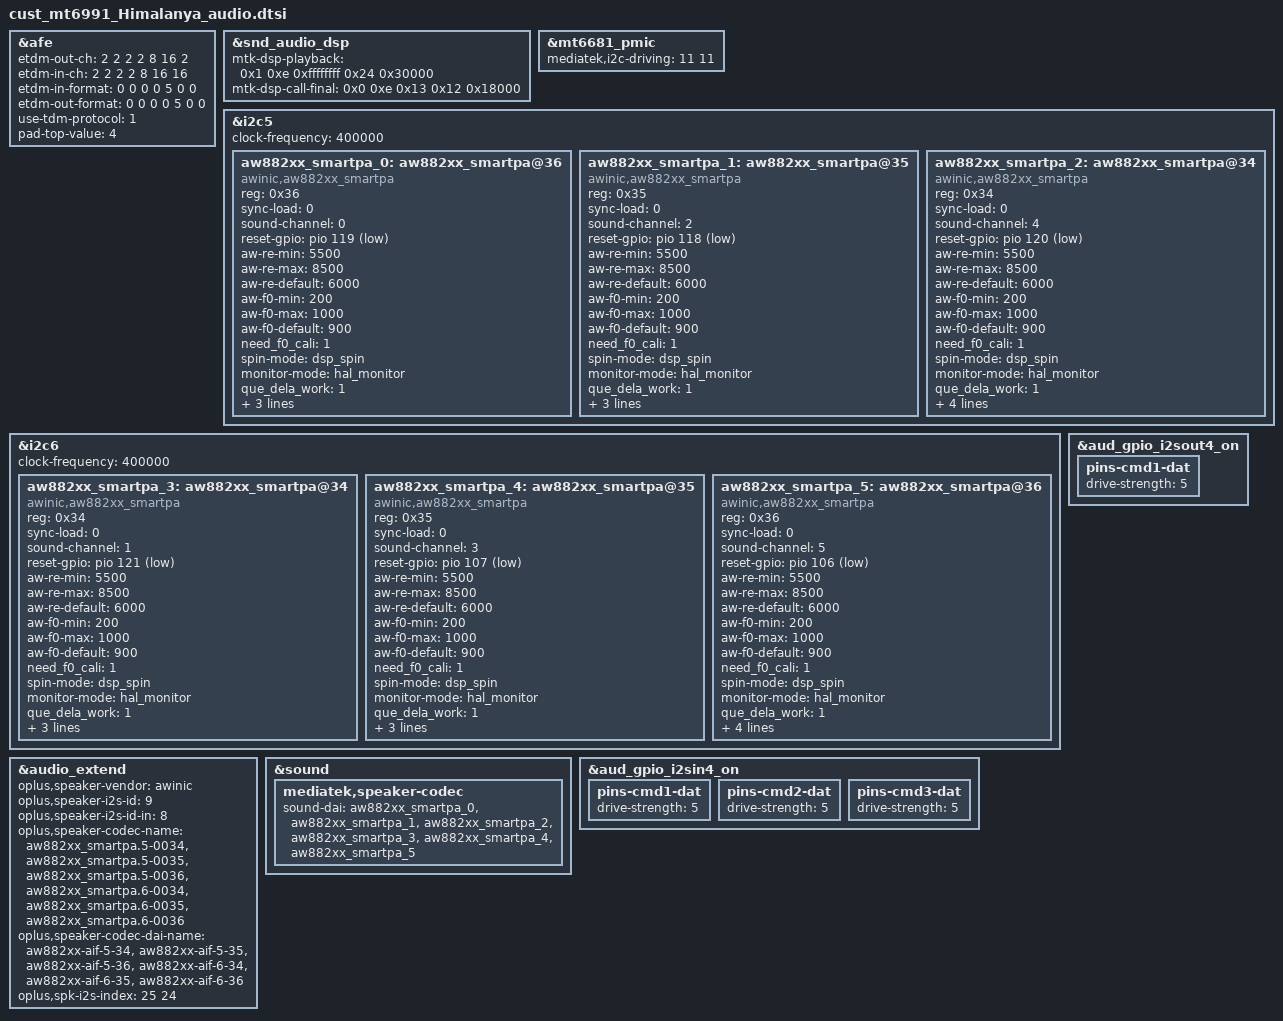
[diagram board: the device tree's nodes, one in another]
// SPDX-License-Identifier: GPL-2.0
/* Copyright (c) 2020 MediaTek Inc. */
#include <dt-bindings/pinctrl/mt6373-pinfunc.h>

&afe {
    etdm-out-ch = <2 2 2 2 8 16 2>;
    etdm-in-ch = <2 2 2 2 8 16 16>;
    etdm-in-format = <0 0 0 0 5 0 0>;
    etdm-out-format = <0 0 0 0 5 0 0>;
    use-tdm-protocol = <1>;
    pad-top-value = <4>;
};


&snd_audio_dsp {
    mtk-dsp-playback = <0x1 0xe 0xffffffff 0x24 0x30000>;
    mtk-dsp-call-final = <0x0 0xe 0x13 0x12 0x18000>;
};

&mt6681_pmic {
	mediatek,i2c-driving = <11 11>;
};

&i2c5 {
	clock-frequency = <400000>;

/* AWINIC AW882XX mono Smart PA */

aw882xx_smartpa_0: aw882xx_smartpa@36 {
	 compatible = "awinic,aw882xx_smartpa";
	 reg = <0x36>;
	 #address-cells = <1>;
	 #size-cells = <0>;
	 #sound-dai-cells = <0>;
	 sync-load = <0>;
	 sound-channel = <0>;
	 reset-gpio = <&pio 119 0x1>;
	 aw-re-min = <5500>;
	 aw-re-max= <8500>;
	 aw-re-default = <6000>;
	 aw-f0-min = <200>;
	 aw-f0-max = <1000>;
	 aw-f0-default = <900>;
	 //aw-cali-mode = "none";
	 need_f0_cali = <1>;
	 spin-mode = "dsp_spin";
	 monitor-mode = "hal_monitor";
	 que_dela_work = <1>;
	 fade-flag = <0>;
	 need-add-bus-id = <1>;
	 default-chip-id = <0x2113>;
	 status = "okay";
};

aw882xx_smartpa_1: aw882xx_smartpa@35 {
	 compatible = "awinic,aw882xx_smartpa";
	 reg = <0x35>;
	 #address-cells = <1>;
	 #size-cells = <0>;
	 #sound-dai-cells = <0>;
	 sync-load = <0>;
	 sound-channel = <2>;
	 reset-gpio = <&pio 118 0x1>;
	 aw-re-min = <5500>;
	 aw-re-max= <8500>;
	 aw-re-default = <6000>;
	 aw-f0-min = <200>;
	 aw-f0-max = <1000>;
	 aw-f0-default = <900>;
	 //aw-cali-mode = "none";
	 need_f0_cali = <1>;
	 spin-mode = "dsp_spin";
	 monitor-mode = "hal_monitor";
	 que_dela_work = <1>;
	 fade-flag = <0>;
	 need-add-bus-id = <1>;
	 default-chip-id = <0x2113>;
	 status = "okay";
};

aw882xx_smartpa_2: aw882xx_smartpa@34 {
	 compatible = "awinic,aw882xx_smartpa";
	 reg = <0x34>;
	 #address-cells = <1>;
	 #size-cells = <0>;
	 #sound-dai-cells = <0>;
	 sync-load = <0>;
	 sound-channel = <4>;
	 reset-gpio = <&pio 120 0x1>;
	 aw-re-min = <5500>;
	 aw-re-max= <8500>;
	 aw-re-default = <6000>;
	 aw-f0-min = <200>;
	 aw-f0-max = <1000>;
	 aw-f0-default = <900>;
	 //aw-cali-mode = "none";
	 need_f0_cali = <1>;
	 spin-mode = "dsp_spin";
	 monitor-mode = "hal_monitor";
	 que_dela_work = <1>;
	 fade-flag = <0>;
	 need-add-bus-id = <1>;
	 default-chip-id = <0x2113>;
	 cali-disable = <1>;
	 status = "okay";
};

};

&i2c6 {
	clock-frequency = <400000>;

/* AWINIC AW882XX mono Smart PA */

aw882xx_smartpa_3: aw882xx_smartpa@34 {
	 compatible = "awinic,aw882xx_smartpa";
	 reg = <0x34>;
	 #address-cells = <1>;
	 #size-cells = <0>;
	 #sound-dai-cells = <0>;
	 sync-load = <0>;
	 sound-channel = <1>;
	 reset-gpio = <&pio 121 0x1>;
	 aw-re-min = <5500>;
	 aw-re-max= <8500>;
	 aw-re-default = <6000>;
	 aw-f0-min = <200>;
	 aw-f0-max = <1000>;
	 aw-f0-default = <900>;
	 //aw-cali-mode = "none";
	 need_f0_cali = <1>;
	 spin-mode = "dsp_spin";
	 monitor-mode = "hal_monitor";
	 que_dela_work = <1>;
	 fade-flag = <0>;
	 need-add-bus-id = <1>;
	 default-chip-id = <0x2113>;
	 status = "okay";
};

aw882xx_smartpa_4: aw882xx_smartpa@35 {
	 compatible = "awinic,aw882xx_smartpa";
	 reg = <0x35>;
	 #address-cells = <1>;
	 #size-cells = <0>;
	 #sound-dai-cells = <0>;
	 sync-load = <0>;
	 sound-channel = <3>;
	 reset-gpio = <&pio 107 0x1>;
	 aw-re-min = <5500>;
	 aw-re-max= <8500>;
	 aw-re-default = <6000>;
	 aw-f0-min = <200>;
	 aw-f0-max = <1000>;
	 aw-f0-default = <900>;
	 //aw-cali-mode = "none";
	 need_f0_cali = <1>;
	 spin-mode = "dsp_spin";
	 monitor-mode = "hal_monitor";
	 que_dela_work = <1>;
	 fade-flag = <0>;
	 need-add-bus-id = <1>;
	 default-chip-id = <0x2113>;
	 status = "okay";
};

aw882xx_smartpa_5: aw882xx_smartpa@36 {
	 compatible = "awinic,aw882xx_smartpa";
	 reg = <0x36>;
	 #address-cells = <1>;
	 #size-cells = <0>;
	 #sound-dai-cells = <0>;
	 sync-load = <0>;
	 sound-channel = <5>;
	 reset-gpio = <&pio 106 0x1>;
	 aw-re-min = <5500>;
	 aw-re-max= <8500>;
	 aw-re-default = <6000>;
	 aw-f0-min = <200>;
	 aw-f0-max = <1000>;
	 aw-f0-default = <900>;
	 //aw-cali-mode = "none";
	 need_f0_cali = <1>;
	 spin-mode = "dsp_spin";
	 monitor-mode = "hal_monitor";
	 que_dela_work = <1>;
	 fade-flag = <0>;
	 need-add-bus-id = <1>;
	 default-chip-id = <0x2113>;
	 cali-disable = <1>;
	 status = "okay";
};

};


&audio_extend {
 	//for nxp speaker
 	oplus,speaker-vendor = "awinic";
 	oplus,speaker-i2s-id = <9>;
 	oplus,speaker-i2s-id-in = <8>;
	oplus,speaker-codec-name = "aw882xx_smartpa.5-0034", "aw882xx_smartpa.5-0035", "aw882xx_smartpa.5-0036","aw882xx_smartpa.6-0034", "aw882xx_smartpa.6-0035", "aw882xx_smartpa.6-0036";
	oplus,speaker-codec-dai-name = "aw882xx-aif-5-34", "aw882xx-aif-5-35", "aw882xx-aif-5-36", "aw882xx-aif-6-34", "aw882xx-aif-6-35", "aw882xx-aif-6-36";
	oplus,spk-i2s-index = <25 24>;
	status = "okay";
};

&sound {
//	mtk_spk_i2s_out = <3>;
//	mtk_spk_i2s_in = <9>;
	mediatek,speaker-codec {
		sound-dai = <&aw882xx_smartpa_0 &aw882xx_smartpa_1 &aw882xx_smartpa_2 &aw882xx_smartpa_3 &aw882xx_smartpa_4 &aw882xx_smartpa_5>;
	};
};

&aud_gpio_i2sin4_on {
    pins-cmd1-dat {
        drive-strength = <5>;
    };
    pins-cmd2-dat {
        drive-strength = <5>;
    };
    pins-cmd3-dat {
        drive-strength = <5>;
    };
};

&aud_gpio_i2sout4_on {
    pins-cmd1-dat {
        drive-strength = <5>;
    };
};
